# wsoc_nab_secure register map
Vendor: Texas Instruments
Peripheral module from a debugger description file (folder CC35X1E).
Registers are 32-bit, read-only, reset 0x0 unless marked. A register's access mark holds for its fields unless they carry their own. Offsets are as the file gives them; lines under a group give offsets from that group; [hi:lo] are bit positions; {n}, {i} and the like mark numbered series; 'fields as' and 'values as' point back to an identical list; <NAME> marks a mode.

## wsoc_nab_secure
0x00 nab_command_mailbox_address access per field
  [23:0] MEM_CMD_MBX_ADDR rw
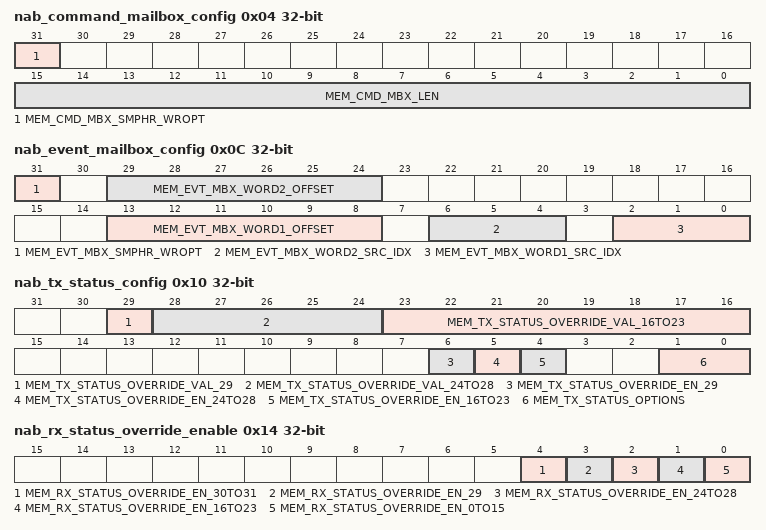
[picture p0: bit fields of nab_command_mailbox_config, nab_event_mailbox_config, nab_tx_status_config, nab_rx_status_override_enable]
0x04 nab_command_mailbox_config access per field
  [31] MEM_CMD_MBX_SMPHR_WROPT rw — Set to "1" by NAB H/W, when a new command arrives. Set to "0" by S/W (by actualy writing "1" to it, i.e. Write Clear) when the corresponding event has been submitted to NAB.
  [15:0] MEM_CMD_MBX_LEN rw — Command mailbox location. Once a command arrives, the fields from the opcode are dumped contiguously on this address. Aside from the opcode and length which are given in system endianness, the remainder of the command is in the endianness of the host.
0x08 nab_event_mailbox_address access per field
  [23:0] MEM_EVT_MBX_ADDR rw — Event mailbox location. S/W fills this block with data, including opcode and len fields, to be sent to the host in the appropriate cnys request. The len field must include the Rx status field, i.e., must be +4 then the remainder of the packet in the event mailbox.
0x0C nab_event_mailbox_config access per field
  [31] MEM_EVT_MBX_SMPHR_WROPT rw — Set to "1" by S/W, when the event address and length are filled up with a new event. Note that the NAB H/W then signals the host (IRQ line) when this is set, to ask the host to issue cnys request. Set to "0" by NAB, when the event has been fully consumed by the host.
  [29:24] MEM_EVT_MBX_WORD2_OFFSET rw — Indicates the added word nr.2 (if exists) offset location within the response sequence: "0" - N.A (this is OP-LEN field offset location) "1" - Place word nr.2 in word offset 1 (right after OP-LEN field) "2" - Place word nr.2 in word offset 2 "3" - Place word nr.2 in word offset 3 etc... NOTE: in WORD 2 exsits, WORD2_OFFSET > WORD1_OFFSET should be applied.
  [13:8] MEM_EVT_MBX_WORD1_OFFSET rw — Indicates the added word nr.1 (if exists) offset location within the response sequence: "0" - N.A (this is OP-LEN field offset location) "1" - Place word nr.1 in word offset 1 (right after OP-LEN field) "2" - Place word nr.1 in word offset 2 "3" - Place word nr.1 in word offset 3 etc...
  [6:4] MEM_EVT_MBX_WORD2_SRC_IDX rw — Nab supports adding info words toward host during event mailbox response. This field Indicates the source of word nr. 2: "0" - feature disabled (do not add any word). Nab transfers mailbox As-is. "1" - source is nab_srp_skt_not_empty_vec - the monitored-only Rx FIFO non-empty sockets (note that monitored sockets are configured in MEM_SRP_SKT_MONITORED_VEC) "2" - source is timer count. i.e. the always-on-domain counter is used. "3-6" - TBD "7" - source is an OCP mapped memory read (mostly for reading any register which is not mapped by index 1 to 6)
  [2:0] MEM_EVT_MBX_WORD1_SRC_IDX rw — Nab supports adding info words toward host during event mailbox response. This field Indicates the source of word nr. 1: "0" - feature disabled (do not add any word). Nab transfers mailbox As-is. "1" - source is nab_srp_skt_not_empty_vec - the monitored-only Rx FIFO non-empty sockets (note that monitored sockets are configured in MEM_SRP_SKT_MONITORED_VEC) "2" - source is timer count. i.e. the always-on-domain counter is used. "3-6" - TBD "7" - source is an OCP mapped memory read (mostly for reading any register which is not mapped by index 1 to 6)
0x10 nab_tx_status_config access per field
  [29] MEM_TX_STATUS_OVERRIDE_VAL_29 rw
  [28:24] MEM_TX_STATUS_OVERRIDE_VAL_24TO28 rw
  [23:16] MEM_TX_STATUS_OVERRIDE_VAL_16TO23 rw
  [6] MEM_TX_STATUS_OVERRIDE_EN_29 rw
  [5] MEM_TX_STATUS_OVERRIDE_EN_24TO28 rw
  [4] MEM_TX_STATUS_OVERRIDE_EN_16TO23 rw
  [1:0] MEM_TX_STATUS_OPTIONS rw — 00 - default: 1 word TX status 01 - Synced (wrapped): 3 words - Sync pattern,OP_LEN (LEN=4) and TX status. 11 - No status 10 - N.A In BSD_BYPASS=1 (Osprey) should be set to 11 - No Status
0x14 nab_rx_status_override_enable access per field
  [4] MEM_RX_STATUS_OVERRIDE_EN_30TO31 rw, [3] MEM_RX_STATUS_OVERRIDE_EN_29 rw, [2] MEM_RX_STATUS_OVERRIDE_EN_24TO28 rw, [1] MEM_RX_STATUS_OVERRIDE_EN_16TO23 rw, [0] MEM_RX_STATUS_OVERRIDE_EN_0TO15 rw
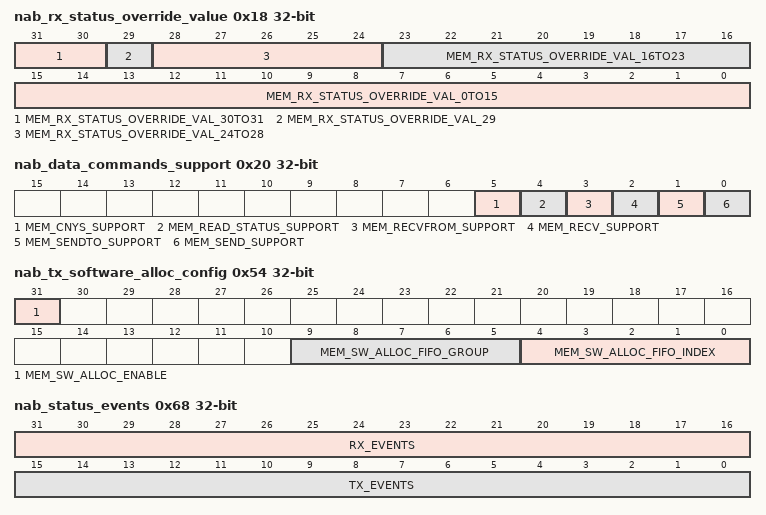
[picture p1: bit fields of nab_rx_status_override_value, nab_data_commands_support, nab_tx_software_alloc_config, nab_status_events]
0x18 nab_rx_status_override_value rw
  [31:30] MEM_RX_STATUS_OVERRIDE_VAL_30TO31, [29] MEM_RX_STATUS_OVERRIDE_VAL_29, [28:24] MEM_RX_STATUS_OVERRIDE_VAL_24TO28, [23:16] MEM_RX_STATUS_OVERRIDE_VAL_16TO23, [15:0] MEM_RX_STATUS_OVERRIDE_VAL_0TO15
0x1C nab_rx_pending_timeout_periord
  [31:0] Reserved — When timeout mechanism is supported in h/w (currently not), this register contains MEM_PENDING_TIMEOUT_PERIOD[29:0] that specify the time in AOD counter cycles between socket gets pending to socket expiry event (pending timeout duration).
0x20 nab_data_commands_support access per field reset not defined
  [5] MEM_CNYS_SUPPORT rw, [4] MEM_READ_STATUS_SUPPORT rw, [3] MEM_RECVFROM_SUPPORT rw, [2] MEM_RECV_SUPPORT rw, [1] MEM_SENDTO_SUPPORT rw, [0] MEM_SEND_SUPPORT rw
0x24 nab_d2h_sync_pattern rw
  [31:0] MEM_D2H_SYNC_PATTERN
0x28 nab_cnys_pattern rw reset not defined
  [31:0] MEM_CNYS_PATTERN
0x2C nab_sync_pattern rw reset not defined
  [31:0] MEM_SYNC_PATTERN
0x34 nab_tx_host_desc_config
  [31:0] TX_DESC_CONFIG
0x38 nab_tx_host_desc_port_padding
  [31:0] DESC_PORT_PADDING
{0x3C+4i} nab_tx_host_desc_peer_addr_w{i} (i=0..4)
  [31:0] DESC_PEER_ADDR_W{i}
0x50 nab_tx_host_tcw
0x54 nab_tx_software_alloc_config access per field reset not defined
  [31] MEM_SW_ALLOC_ENABLE rw — 1 - MMU Bypass mode: it is FW responsibility to allocate Pram for incoming TX Packet. 0 - Default mode: it is NAB responsibility to allocate Pram for incoming TX Packet.
  [9:5] MEM_SW_ALLOC_FIFO_GROUP rw — A User defined FIFO Group from which NAB obtains a descriptor index when SW_ALLOC_ENABLE=1. Otherwise, Nab obtains desc index from MMU.
  [4:0] MEM_SW_ALLOC_FIFO_INDEX rw — A User defined FIFO Index from which NAB obtains a descriptor index when SW_ALLOC_ENABLE=1. Otherwise, Nab obtains desc index from MMU. Elaboration: S/W Allocation is descriptor-index based. Each descriptor is mapped directly to a flat memory which contains a full sized packet (2KiB). This means that every packet consumes the same memory. A pool of free descriptors, and therefore, their associated memory packets are also available, is managed by a specially designated free descriptor index FIFO. Therefore, allocation is made by reading the FIFO and obtaining a real descriptor index (if the FIFO is empty, a null index is returned). Deallocation is done by writing to the FIFO a descriptor index to be freed.
0x58 nab_socket_max_index access per field reset not defined
  [4:0] MEM_SKT_MAX_IDX rw — indicated the maximun index of socket ID. implies on number of sockets (Nab POV) in the device. In case host request data comand (send(), recv() etc..) with socket ID bigger than this value, device responses w/ EBADF. Explicitly: 0 - socket 0 is can be issued by host 1 - sockets 0 and 1 can be issued by host 2 - sockets 0,1 and 2 can be issued by host 3 - sockets 0,1,2 and 3 can be issued by host .. .. .. 31 - sockets 0,1,2...,30,31 can be issued by host
0x5C nab_timeouted_socket_smphr rw
  [31:0] MEM_TIMEOUTED_SKT_SMPHR_WROPT — A bit per socket indicating this socket has been timeout. Set by H/W upon a PENDING socket reached it's timeout period. Reset by S/W upon data arrives to this socket or when it whishes to flush it. NOTE: when this bit set, H/W will keep socket in PENDING state even if it rx data FIFO is not empty.
0x60 nab_host_fifo_threshold access per field reset not defined
  [3:0] MEM_HOST_FIFO_TH rw — This number is the nab to host FIFO threshold. All reads issued to (by host) FIFO are stalled untill FIFO is filled above this threshold. Once the threshold reached FIFO is being read regardless of the threshold. Effective in RCV case only. The motivation is to avoid FIFO underflow. in Osprey (BSD_BYPASS = 1) this threshold is not applicable. The reason for that is that unlike SPI, in SDIO, we have back-pressure in the form of scmdaccept. The SDIO can store SDIO block and can bare the wait-states while waiting till Nab is ready to be read.
0x64 nab_cnys_select_config access per field
  [0] MEM_CNYS_SEL_ROUND_ROBIN rw — cyns response policy for active (cnysable) sockets: 0 - fix priority: selects socket with the lowest index. 1 - round robin priority: lowest index from last selected. Prevents socket starvation. default is fixed priority (0)
0x68 nab_status_events
  [31:16] RX_EVENTS, [15:0] TX_EVENTS
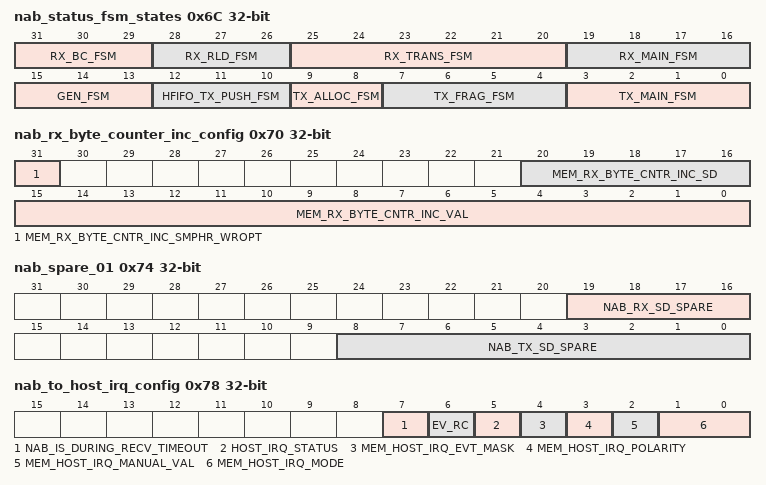
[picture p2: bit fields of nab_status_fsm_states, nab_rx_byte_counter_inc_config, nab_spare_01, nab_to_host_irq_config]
0x6C nab_status_fsm_states
  [31:29] RX_BC_FSM — ----- RX Byte Counter FSM ----------------------- BC_IDLE = 3'd0, GET_VAL = 3'd1, GET_SKT = 3'd2, V_S_CAP = 3'd3, BC_RD = 3'd4, BC_CAP = 3'd5, BC_WR = 3'd6; W_STATE = 3'd7;
  [28:26] RX_RLD_FSM — ----- RX RELOAD FSM ----------------------------- RLD_IDLE = 3'd0, RLD_GET_SKT = 3'd1, RLD_CAP_SKT = 3'd2, RLD_RD_TIMESTAMP = 3'd3, RLD_CAP_TIMESTAMP = 3'd4;
  [25:20] RX_TRANS_FSM — ----- RX TRANS FSM ------------------------------ TRANS_IDLE = 6'd0 , ------- collect ------- PEEK_VSUD = 6'd1 , CAP_VSUD = 6'd2 , COLLECT_SUD = 6'd3 , GET_NXT = 6'd4 , ACC_LEN = 6'd5 , ------- response ------- WAIT4_EMPTY = 6'd6 , SYNC = 6'd7 , OP_LEN = 6'd8 , RX_STATUS = 6'd9 , DESC_CFG = 6'd10, PORT_PAD = 6'd11, PEER_W0 = 6'd12, PEER_W1 = 6'd13, PEER_W2 = 6'd14, PEER_W3 = 6'd15, PEER_W4 = 6'd16, CAP_IP = 6'd17, SET_TCW = 6'd18, ------- payload ------- POP_VSUD = 6'd19, RD_SUD1 = 6'd20, RD_SUD2 = 6'd21, RD_PA = 6'd22, CAP_PA = 6'd23, RD_DATA = 6'd24, UPD_SUD1 = 6'd25, UPD_SUD2 = 6'd26, DEALLOC_SUD = 6'd27, DEALLOC_DESC = 6'd28, RCV_DONE = 6'd29, CHK_FIFO = 6'd30, BYTE_CNT_INC = 6'd31, BYTE_CNT_DEC = 6'd32, PUSH_HEAD = 6'd33; ADDR_CAP = 6'd34;
  [19:16] RX_MAIN_FSM — ----- RX MAIN FSM ------------------------------- IDLE = 4'd0, DESC = 4'd1, TCW = 4'd2, BUSY = 4'd3, HDR_DONE = 4'd4, SOCKET_RD = 4'd5, EVAL_REQ = 4'd6, RETAIN_SOCKET_STATE = 4'd7, COLLECT_LEN = 4'd8, RX_RESPONSE = 4'd9;
  [15:13] GEN_FSM — ----- GEN FSM ----------------------------------- IDLE = 4'd0 CAPTURE_OP_LEN = 4'd1 HANDLE_SND_REQ = 4'd2 HANDLE_RCV_REQ = 4'd3 CNYS_ON_RCV_BUSY = 4'd4 RCV_ON_RCV_BUSY = 4'd5 SND_ON_RCV_BUSY = 4'd6 CAPTURE_RX_DESC_CFG = 4'd7 CAPTURE_RX_TCW = 4'd8 (Apears as 0 as we occupied only 3 LSB's)
  [12:10] HFIFO_TX_PUSH_FSM — ----- Host FIFO TX PUSH FSM --------------------- TX_PUSH_IDLE = 3'd0, WAIT4_RCV_DONE = 3'd1, TX_PUSH_SYNC = 3'd2, TX_PUSH_OP_LEN = 3'd3, TX_PUSH_STATUS = 3'd4;
  [9:8] TX_ALLOC_FSM — ----- TX ALLOC FSM ------------------------------ GET_ALLOC_IDLE = 2'd0, GET_ALLOC_WR_REQ = 2'd1, GET_ALLOC_GET_IRQ = 2'd2, GET_ALLOC_RD_RSP = 2'd3;
  [7:4] TX_FRAG_FSM — ----- TX FRAGMENTATION FSM ---------------------- FRAG_IDLE = 4'b 0_0_0_0, // 0 FIRST_LAST = 4'b 0_1_1_1, // 7 FIRST_PRE_LAST = 4'b 0_1_0_1, // 5 FIRST = 4'b 1_1_0_1, // d MID = 4'b 0_1_0_0, // 4 PRE_LAST = 4'b 1_1_0_0, // c LAST = 4'b 0_1_1_0; // 6 bit[0]- first indication bit[1]- last indication bit[2]- tx desc write indication bit[3]- Unique bit
  [3:0] TX_MAIN_FSM — ----- TX MAIN FSM ------------------------------- IDLE = 4'd0, DESC = 4'd1, EVAL_REQ = 4'd2, DESC_SENDTO = 4'd3, TCW = 4'd4, SET_ALLOC = 4'd5, SET_DMA_TRANSFER = 4'd6, DMA_TRANSFER = 4'd7, SET_LAST_FRAG = 4'd8, PUSH = 4'd9, JOIN = 4'd10, DEALLOC = 4'd11, DROP_PACKET = 4'd12, ALLOC_FIRST = 4'd13, TX_STATUS = 4'd14;
0x70 nab_rx_byte_counter_inc_config access per field
  [31] MEM_RX_BYTE_CNTR_INC_SMPHR_WROPT rw — Set to "1" by S/W once an rx packet arrives to rx pipeline. Set to "0" by H/W once the NAB acknowledges the S/W request to increment (in a signed way) the byte counter
  [20:16] MEM_RX_BYTE_CNTR_INC_SD rw — Identifies the socket ID (socket database's entry) for which Rx byte count is to be updated.
  [15:0] MEM_RX_BYTE_CNTR_INC_VAL rw — The value designates a signed 16 bit value to be added (or decremented if negative) to a given socket's Rx byte count. The NAB would update the relevant Rx byte count safely using MEM_RX_BYTE_COUNTER_SMPHR. Protocol: 1. The S/W determines the size to be added to the Rx byte count, once a new packet arrives to the pipe. 2. The S/W then writes to this register the value comprising both the socket (MEM_RX_BYTE_CNTR_INC_SD) and number to add (MEM_RX_BYTE_CNTR_INC_VAL). 3. NAB H/W safely updates the socket entry.
0x74 nab_spare_01
  [19:16] NAB_RX_SD_SPARE — For future ECO usage. H/W gets socket database info per socket
  [8:0] NAB_TX_SD_SPARE — For future ECO usage. H/W gets socket database info per socket
0x78 nab_to_host_irq_config access per field
  [7] NAB_IS_DURING_RECV_TIMEOUT ro — Indication that Nab got recv request to socket with no data (empty fifo) and recv tiomeout indication at this socket is set. Nab sets this socket to PENDING state, reads current timest + timeout period and waits for either data arrival to this socket fifo or to timeout expiry event.
  [6] EV_RC ro — Event-Receive Bit: 1 - at least one of 32 sockets is in Active state (a pending socket that is now ready to be issued) OR S/W set Event MBX semaphore and CNYS is yet to arrive (EVT-MBX contains unissued event) 0 - No Active socket and Event Mailbox is empty. Note: 1. ev_rc bit is the Host IRQ initiator. In "Level mode" IRQ: ec_rc == HOST_IRQ_STATUS. In other modes - this bit is manipulated in order to create proper IRQ line toward the host. 2. A mask bit per socket, mem_host_irq_rcv_mask[31:0], can be set in order to prevent ev_rc 3. A mask bit, mem_host_irq_evt_mask, can be set in order to prevent ev_rc
  [5] HOST_IRQ_STATUS ro — Presents status of IRQ line using positive polarity.
  [4] MEM_HOST_IRQ_EVT_MASK rw — "1" Disable the event mailbox as a host IRQ trigger "0" Enable the event mailbox as a host IRQ trigger
  [3] MEM_HOST_IRQ_POLARITY rw — "1" for negative polarity "0" for positive polarity (GuyS: in order to preserve this at sleep (retention) - ISO latch needs to be implementd. Alternatively, move this polarity cfg bit to upper H/W layer above Nab)
  [2] MEM_HOST_IRQ_MANUAL_VAL rw — Defines the value of the host IRQ line in manual mode operation
  [1:0] MEM_HOST_IRQ_MODE rw — Defines the method of operation of the host IRQ line: "00" Manual "01" CC31xx level mode of operation "10" Level mode of operation "11" Edge mode of operation
0x7C nab_to_host_irq_rcv_mask rw
  [31:0] MEM_HOST_IRQ_RCV_MASK — Bit per socket filed. bit x = "1": Disable the Active Rx socket nr. x as a host IRQ trigger bit x = "0": Enable the Active Rx socket nr. x as a host IRQ trigger
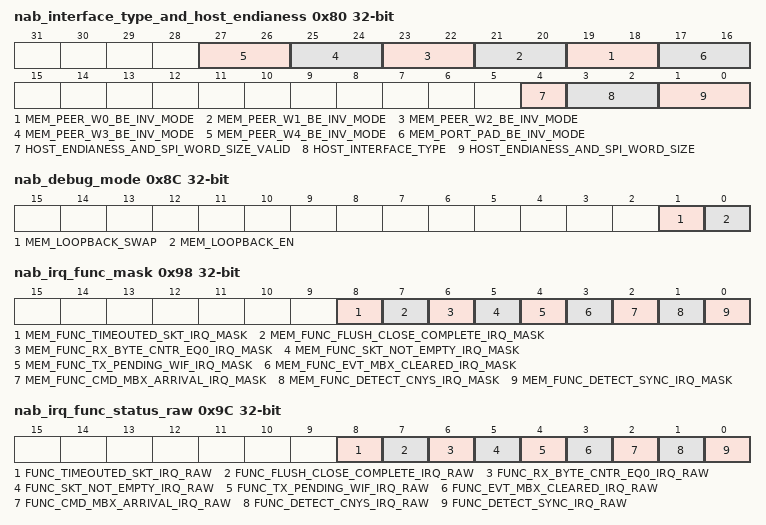
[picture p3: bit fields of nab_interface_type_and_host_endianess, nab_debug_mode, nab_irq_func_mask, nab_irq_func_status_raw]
0x80 nab_interface_type_and_host_endianess access per field
  [2n+19:2n+18] MEM_PEER_W{n}_BE_INV_MODE rw (n=0..4) — Multi byte field inversion of peer parameters for Big Endianess host: 0 - no inversion (in case word structure is four 8-bit integers). 1 - word 2B/2B byte inversion (in case word structure is 2 shorts). 2 - full 4B inversion (in case word structure 32-bit integer). 3 - N.A
  [17:16] MEM_PORT_PAD_BE_INV_MODE rw — Multi byte field inversion of peer parameters for Big Endianess host: 0 - no inversion (in case word structure is four 8-bit integers). 1 - word 2B/2B byte inversion (in case word structure is 2 shorts). 2 - full 4B inversion (in case word structure 32-bit integer). 3 - N.A
  [4] HOST_ENDIANESS_AND_SPI_WORD_SIZE_VALID ro — Indicates host's endianess and SPI word size. 0 - LE-32, 1 - LE-16, 2 - LE-8, 3 - BE, Note: assumption is that SPI interfaces works MSB first.
  [3:2] HOST_INTERFACE_TYPE ro — Indicates Interface Type according to input ports (from Nab interface adaptor). 0 - AHB 1 - SPI 2 - UART 3 - Undetected_yet. No cnys/sync detection occurred. NOTE: HOST_INTEWRFACE TYPE = 3 means that no SYNC/CNYS detection occurred. therfore, the content of HOST_ENDIANESS_AND_SPI_WORD_SIZE is not valid as well. SW should read these fielsd only after SYNC/CNYS detect interrupt are set. IMPORTANT: Currrently it is hard coded, tied in h/w value: in BSD_BYPASS=1 (Osprey) tied to 3. in BSD_BYPASS=0 (Not Osprey) tied to 1.
  [1:0] HOST_ENDIANESS_AND_SPI_WORD_SIZE ro — Indicates host's endianess and SPI word size. 0 - LE-32, 1 - LE-16, 2 - LE-8, 3 - BE, Note: assumption is that SPI interfaces works MSB first.
0x84 nab_socket_state_00_to_15 rw
  [31:0] MEM_SOCKET_STATE_00_TO_15_WROPT — Socket 0 to 15 state register: bit [2x+1:2x] = "00" - Socket x is IDLE "01" - Socket x is Pending "10" - Socket x is Active "11" - N.A Pending state occurs when blocking socket recives host request and related Rx FIFO is empty. Active state occurs when pending socket recives data or pending-timeout occurs. Active means that the socket is applicable for CNYS. NOTE: 1. Socket that is not pending and not active is considered to be IDLE, i.e. ready to receive host request. 2. S/W can write this reg. This enable restoring socket state after ELP. writing less than a byte is not allowed. 3. If socket is written by S/W as PENDING it will be considered as if no timeout was enabled (we cannot restore a socket to PENDING with timeout period on).
0x88 nab_socket_state_16_to_31 rw
  [31:0] MEM_SOCKET_STATE_16_TO_31_WROPT — Socket 16 to 31state register: bit [2x+1:2x] = "00" - Socket 16+x is IDLE "01" - Socket 16+x is Pending "10" - Socket 16+x is Active "11" - N.A Pending state occurs when blocking socket recives host request and related Rx FIFO is empty. Active state occurs when pending socket recives data or pending-timeout occurs. Active means that the socket is applicable for CNYS. NOTE: 1. Socket that is not pending and not active is considered to be IDLE, i.e. ready to receive host request. 2. S/W can write this reg. This enable restoring socket state after ELP. writing less than a byte is not allowed. 3. If socket is written by S/W as PENDING it will be considered as if no timeout was enabled (we cannot restore a socket to PENDING with timeout period on).
0x8C nab_debug_mode access per field
  [1] MEM_LOOPBACK_SWAP rw — 0 - loopback word swap is disabled 1 - loopback word swap is enabled when loopback mode is enabled, nab examines the host incoming words and search for a pre defined pattern. Once this pattern is detected, it is swapped (16 LSB and 16 MSB are swiched) before pushing it back to host like any other word. The pre define pattern, `LOOPBACK_WORD, can be found in wsoc_nab_defines.v e.g. word pattern: 0x76543210 host stream to nab: ...,0x49a9, 0x5, 0x8675d, 0x7653b, 0x76543210, 0x6745b3c, 0x65d,... nab stream back to host: ...,0x49a9, 0x5, 0x8675d, 0x7653b, 0x32107654, 0x6745b3c, 0x65d,...
  [0] MEM_LOOPBACK_EN rw — 0 - loopback mode is disabled 1 - loopback mode is enabled In Loopback mode any word written by host to nab via data ocp slave port is returned back to host. Nab pushes the incoming word straight to FIFO toward host.
0x90 nab_flush_close_command_sel access per field
  [0] MEM_FLUSH_CLOSE_SEL rw — 1 - FLUSH command 0 - CLOSE command
0x94 nab_flush_close_command_smphr rw
  [31:0] MEM_FLUSH_CLOSE_SMPHR_WROPT — Bit per socket that supports Both FLUSH and CLOSE commands request (according to MEM_FLUSH_CLOSE_SEL) settings at the time of the request: Set to "1" by SW as request to flush or close request (one at a time), possibly to more than one socket. Set to "0" by H/W once command is completed FLUSH: Once set by S/W Nab looks for the nearest opportunity to clear it, indicating that the socket is flushed. The nearest opportunity is as follow: in case socket is occupied - wait till it clears. In case socket is not occupied and not pending - the socket can be "Flushed" immediately. Nab Clears the semaphore and triggers S/W with flush_close IRQ. In case socket is not occupied but is pending - the socket cannot be "Flushed" immediately. Nab moves the socket to active and waits for host CNYS. Once arrived, answer the CNYS with Disallowed (and not ENODATAC), clears the semaphore and triggers S/W with flush_close IRQ. NOTE: it is NWP S/W responsibility to disallowed the socket before flushing it. CLOSE: Once set by S/W Nab looks for the nearest opportunity to clear it, indicating that the socket is closed. The nearest opportunity is as follow: in case socket is occupied - wait till it clears. In case socket is not occupied - the socket can be "Closed" immediately. Nab Clears the semaphore and triggers S/W with flush_close IRQ. NOTE: it is NWP S/W responsibility to close socket only if it is in IDLE state (and after closing the socket, i.e. setting "111...", in socket jump table).
0x98 nab_irq_func_mask access per field — Mask interrupt bits: when set to "1", the interrupt is masked, and NOT be reflected to user.
  [8] MEM_FUNC_TIMEOUTED_SKT_IRQ_MASK rw, [7] MEM_FUNC_FLUSH_CLOSE_COMPLETE_IRQ_MASK rw, [6] MEM_FUNC_RX_BYTE_CNTR_EQ0_IRQ_MASK rw, [5] MEM_FUNC_SKT_NOT_EMPTY_IRQ_MASK rw, [4] MEM_FUNC_TX_PENDING_WIF_IRQ_MASK rw, [3] MEM_FUNC_EVT_MBX_CLEARED_IRQ_MASK rw, [2] MEM_FUNC_CMD_MBX_ARRIVAL_IRQ_MASK rw, [1] MEM_FUNC_DETECT_CNYS_IRQ_MASK rw, [0] MEM_FUNC_DETECT_SYNC_IRQ_MASK rw
0x9C nab_irq_func_status_raw — Unmasked Interrupt status bits.
  [8] FUNC_TIMEOUTED_SKT_IRQ_RAW, [7] FUNC_FLUSH_CLOSE_COMPLETE_IRQ_RAW, [6] FUNC_RX_BYTE_CNTR_EQ0_IRQ_RAW, [5] FUNC_SKT_NOT_EMPTY_IRQ_RAW, [4] FUNC_TX_PENDING_WIF_IRQ_RAW, [3] FUNC_EVT_MBX_CLEARED_IRQ_RAW, [2] FUNC_CMD_MBX_ARRIVAL_IRQ_RAW, [1] FUNC_DETECT_CNYS_IRQ_RAW, [0] FUNC_DETECT_SYNC_IRQ_RAW
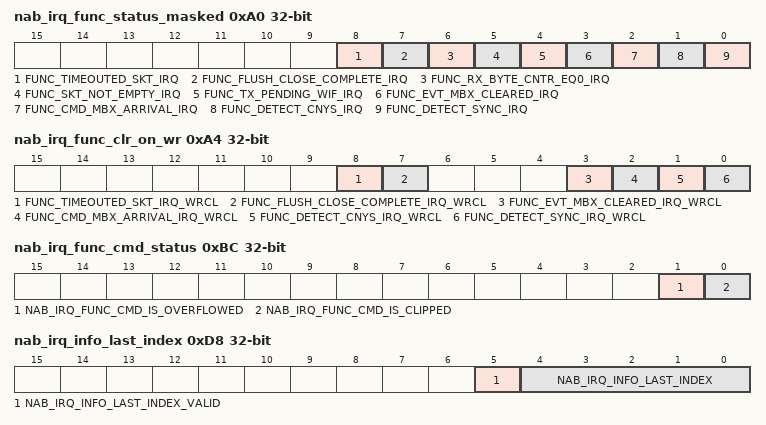
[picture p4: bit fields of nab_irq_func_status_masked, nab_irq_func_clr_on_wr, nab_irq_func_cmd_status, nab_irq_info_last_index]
0xA0 nab_irq_func_status_masked — Interrupt status bits - Masked according to NAB_IRQ_FUNC_MASK.
  [8] FUNC_TIMEOUTED_SKT_IRQ — Set by H/W upon socket's PENDING period timeout has reached. Clear by S/W using FUNC_TIMEOUTED_SKT_IRQ_WRCL.
  [7] FUNC_FLUSH_CLOSE_COMPLETE_IRQ — Set by H/W upon completion of S/W "Flush" or "Close" request (one socket or more). Clear by S/W using FUNC_FLUSH_CLOSE_COMPLETE_IRQ_WRCL. NOTE: the IRQ is set at even if there are othere sockets with ongoing Flush/Close requests.
  [6] FUNC_RX_BYTE_CNTR_EQ0_IRQ — Set by H/W when at least one bit of NAB_IRQ_FUNC_RX_BC0_SKT_IDX is set to "1". Clear by H/W when All bits of NAB_IRQ_FUNC_RX_BC0_SKT_IDX are equal to "0".
  [5] FUNC_SKT_NOT_EMPTY_IRQ — Set by H/W when at least one bit of NAB_SRP_SKT_NOT_EMPTY_VEC is set to "1". Clear by H/W when All bits of NAB_SRP_SKT_NOT_EMPTY_VEC are equal to "0".
  [4] FUNC_TX_PENDING_WIF_IRQ — Set by H/W when at least one bit of NAB_IRQ_FUNC_TX_WIF_SKT_IDX is set to "1". Clear by H/W when All bits of NAB_IRQ_FUNC_TX_WIF_SKT_IDX are equal to "0".
  [3] FUNC_EVT_MBX_CLEARED_IRQ — Set by H/W upon reading ALL data from event mailbox. Clear by S/W using FUNC_EVT_MBX_ARRIVAL_IRQ_WRCL.
  [2] FUNC_CMD_MBX_ARRIVAL_IRQ — Set by H/W upon generic Command detection from host. Clear by S/W using FUNC_CMD_MBX_ARRIVAL_IRQ_WRCL.
  [1] FUNC_DETECT_CNYS_IRQ — Set by H/W upon CNYS word detection from host. Clear by S/W using FUNC_DETECT_CNYS_IRQ_WRCL.
  [0] FUNC_DETECT_SYNC_IRQ — Set by H/W upon SYNC word detection from host. Clear by S/W using FUNC_DETECT_SYNC_IRQ_WRCL.
0xA4 nab_irq_func_clr_on_wr access per field — Interrupt status clear bits. (clear on WR "1")
  [8] FUNC_TIMEOUTED_SKT_IRQ_WRCL wo, [7] FUNC_FLUSH_CLOSE_COMPLETE_IRQ_WRCL wo, [3] FUNC_EVT_MBX_CLEARED_IRQ_WRCL wo, [2] FUNC_CMD_MBX_ARRIVAL_IRQ_WRCL wo, [1] FUNC_DETECT_CNYS_IRQ_WRCL wo, [0] FUNC_DETECT_SYNC_IRQ_WRCL wo
0xA8 nab_irq_func_tx_wif_skt_idx — Information saved for the interrupt func_tx_pending_wif_irq: bits[31:0] - bit per socket. 1 - This socket has failed to serve a blocking send/sendto operation due to insufficient mem/blk 0 - This socket has NOT failed to serve a blocking send/sendto operation.
0xAC nab_irq_func_tx_wif_skt_idx_clr_on_wr wo — Clear Information saved for the interrupt func_tx_wif_irq: bits[31:0] - bit per socket. 1 - Clear the related socket information bit 0 - Socket's information bit is unchanged
  [31:0] MEM_NAB_IRQ_FUNC_TX_WIF_WRCL
0xB0 nab_irq_func_rx_bc0_skt_idx_en rw — Information configured for the interrupt func_rx_byte_cntr_bc0_irq: bits[31:0] - bit per socket. 1 - Enable "byte counter equal to zero" interrupt for this socket. 0 - Do not set "byte counter equal to zero" interrupt for this socket.
  [31:0] MEM_BYTE_CNTR_EQ_0_INT_EN
0xB4 nab_irq_func_rx_bc0_skt_idx — Information saved for the interrupt func_rx_byte_cntr_bc0_irq: bits[31:0] - bit per socket. 1 - This socket byte counter has just been updated to zero by h/w due to RX descriptor deallocation process. 0 - This socket byte counter has NOT been updated to zero.
0xB8 nab_irq_func_rx_bc0_skt_idx_clr_on_wr wo — Clear Information saved for the interrupt func_rx_byte_cntr_bc0_irq: bits[31:0] - bit per socket. 1 - Clear the related socket information bit 0 - Socket's information bit is unchanged
  [31:0] MEM_NAB_IRQ_FUNC_RX_BC0_WRCL
0xBC nab_irq_func_cmd_status
  [1] NAB_IRQ_FUNC_CMD_IS_OVERFLOWED — SEVERE generic CMD failure: Tx detect overflow during host generic CMD handling (copy data to Mailbox)
  [0] NAB_IRQ_FUNC_CMD_IS_CLIPPED — SEVERE generic CMD failure: t.len < CMD Mailbox size defined by MEM_CMD_MBX_LEN
0xC0 nab_ready access per field
  [0] MEM_NAB_READY rw — 1 - Nab is ready and will monitor host bus for sync/cnys patterns 0 - Nab is not ready and will not monitor host bus for sync/cnys patterns Default is 0
0xC4 nab_irq_info_mask rw — Mask interrupt bits. when set, bit x masks interrupt nr. x. refer to NAB_IRQ_INFO_STATUS_MASKED register for info inrerrupts list
  [31:0] MEM_NAB_IRQ_INFO_MASK
0xC8 nab_irq_info_status_raw — Unmasked Interrupt status bits. bit x states interrupt nr. x refer to NAB_IRQ_INFO_STATUS_MASKED register for info inrerrupts list
0xCC nab_irq_info_status_masked — Interrupt status bits - Masked according to NAB_IRQ_INFO_MASK. INFO Interrupt list: 0 - detect_rcv_cnys ; Operation started - rcv_cnys 1 - detect_evt_cnys ; Operation started - evt_cnys 2 - detect_rds_cnys ; Operation started - rds_cnys 3 - detect_send ; Operation started - send() 4 - detect_sendto ; Operation started - sendto() 5 - detect_recv ; Operation started - recv() 6 - detect_recvfrom ; Operation started - recvfrom() 7 - detect_read_status ; Operation started - read_status() 8 - detect_cmd ; Operation started - generic cmd 9 - rcv_header_done ; Operation ended (Rx header recived at nab) - recv()/recvfrom() 10 - snd_done ; Response (Operation) ended - send()/sendto() (bits 23:22 in info word, desc-cfg, use for opcode decode) 11 - rds_done ; Response (Operation) ended - rd_status() is done 12 - rcv_done ; Response ended - recv()/recvFrom() (bits 23:22 in info word, desc-cfg, use for opcode decode) 13 - cmd_done ; Response ended - generic cmd is fully copied to cmd mbx 14 - evt_done ; Response ended - event from s/w to host is fully sent toward host 15 - err_ebadf ; tx request failure: socket ID > mem_num_of_sockets or socket is not open 16 - err_disallowed ; tx request failure: detect send/sentTo request but send/sentTo is dissallowed 17 - err_eafnosupport ; tx request failure: address family is not allowed - sendTo only 18 - err_emsgsize ; tx request failure: user payload len exceeded socket's max_payload_size 19 - f_alloc_failure ; tx mem resource failure: first fragment MMU request alloc failure 20 - m_alloc_failure ; tx mem resource failure: middle fragment, RIGID socket, MMU request alloc failure - command aborted 21 - m_alloc_partial_len ; tx mem resource missing: middle fragment, Non-RIGID socket, MMU request alloc failure - command success for partial length 22 - err_ewouldblocks ; tx packet_failure_non_blk: mem resource failure (either one of f_alloc_failure, m_alloc_failure or sw_alloc_failure) on a Non-blocking socket 23 - err_enomem ; tx packet_failure_blk : mem resource failure (either one of f_alloc_failure, m_alloc_failure or sw_alloc_failure) on a Blocking socket 24 - err_ebadf ; rx request failure: socket ID > mem_num_of_sockets or socket is not open 25 - err_disallowed ; rx request failure: detect recv/recvFrom request but recv/recvFrom is dissallowed 26 - err_einexe ; rx request failure: detect recv/recvFrom request for PENDING/ACTIVE socket and multiple_recv option is off. 27 - err_einexeselet ; rx request failure: request for socket that is marked for select response monitoring. 28 - err_ewouldblockr ; rx no data failure: detect recv/recvFrom request for non-blocking socket with no data 29 - err_enodatap ; rx no data failure: detect recv/recvFrom request for blocking "IDLE" socket with no data (set socket to "PENDING") 30 - err_enodatac ; rx no data failure: detect CNYS request for blocking "PENDING"/"ACTIVE" socket with no data (which implies that socket got into "ACTIVE" due to timeout) 31 - err_enodatar ; rx no bound failure: detect request over strict socket but no packet boundary is found in sub-desc collection process
0xD0 nab_irq_info_clr_on_wr wo — Interrupt status clear bits. (clear on WR "1") bit x clears interrupt nr. x. refer to NAB_IRQ_INFO_STATUS_MASKED register for info inrerrupts list
  [31:0] MEM_NAB_IRQ_INFO_CLR_WRCL
0xD4 nab_irq_info_word — Information saved for the INFO interrupt: (0 - detect_rcv_cnys ; No info is saved. No info word latching occurs.) (1 - detect_evt_cnys ; No info is saved. No info word latching occurs.) (2 - detect_rds_cnys ; No info is saved. No info word latching occurs.) 3 - detect_send ; transport_op_len 4 - detect_sendto ; transport_op_len 5 - detect_recv ; transport_op_len 6 - detect_recvfrom ; transport_op_len 7 - detect_read_status ; transport_op_len 8 - detect_cmd ; transport_op_len 9 - rcv_header_done ; rx_desc_config_word (bits 23:22 are taken for opcode decode)* 10 - snd_done ; tx_desc_config_word (bits 23:22 are taken for opcode decode)* (11 - rds_done ; No info is saved. No info word latching occurs.) 12 - rcv_done ; rx_desc_config_word (bits 23:22 are taken for opcode decode)* 13 - cmd_done ; transport_op_len 14 - evt_done ; transport_op_len (as read from EVT mailbox) 15 - err_ebadf ; tx_desc_config_word (bits 23:22 are taken for opcode decode)* 16 - err_disallowed ; tx_desc_config_word (bits 23:22 are taken for opcode decode)* 17 - err_eafnosupport ; tx_desc_config_word (bits 23:22 are taken for opcode decode)* 18 - err_emsgsize ; tx_desc_config_word (bits 23:22 are taken for opcode decode)* 19 - f_alloc_failure ; tx_desc_config_word (bits 23:22 are taken for opcode decode)* 20 - m_alloc_failure ; tx_desc_config_word (bits 23:22 are taken for opcode decode)* 21 - m_alloc_partial_len; tx_desc_config_word (bits 23:22 are taken for opcode decode)* 22 - err_ewouldblocks ; tx_desc_config_word (bits 23:22 are taken for opcode decode)* 23 - err_enomem ; tx_desc_config_word (bits 23:22 are taken for opcode decode)* 24 - err_ebadf ; rx_desc_config_word (bits 23:22 are taken for opcode decode)* 25 - err_disallowed ; rx_desc_config_word (bits 23:22 are taken for opcode decode)* 26 - err_einexe ; rx_desc_config_word (bits 23:22 are taken for opcode decode)* 27 - err_einexeselect ; rx_desc_config_word (bits 23:22 are taken for opcode decode)* 28 - err_ewouldblockr ; rx_desc_config_word (bits 23:22 are taken for opcode decode)* 29 - err_enodatap ; rx_desc_config_word (bits 23:22 are taken for opcode decode)* 30 - err_enodatac ; rx_desc_config_word (bits 23:22 are taken for opcode decode)* 31 - err_enodatar ; rx_desc_config_word (bits 23:22 are taken for opcode decode)* where, transport_op_len[15:0] - Host opcode transport_op_len[31:16] - Host length desc_config_word[15:0] - User Length desc_config_word[20:16] - Socket ID desc_config_word[31:24] - Flags * rx_desc_config_word[23:22] opcode decode: 0 - cnys, 1 - recvfrom(), 2 - recv() * tx_desc_config_word[23:22] opcode decode: 1 - sendto() , 2 - send()
0xD8 nab_irq_info_last_index — Indicated Last Unmasked Interrupt index. index x states interrupt nr. x refer to NAB_IRQ_INFO_STATUS_MASKED register for info inrerrupts list
  [5] NAB_IRQ_INFO_LAST_INDEX_VALID, [4:0] NAB_IRQ_INFO_LAST_INDEX
0xDC nab_irq_err_mask access per field — Mask interrupt bits. when set, bit x masks interrupt nr. x. refer to NAB_IRQ_ERR_STATUS_MASKED register for err inrerrupts list
  [8:0] MEM_NAB_IRQ_ERR_MASK rw
0xE0 nab_irq_err_status_raw — Unmasked Interrupt status bits. bit x states interrupt nr. x refer to NAB_IRQ_ERR_STATUS_MASKED register for err inrerrupts list
  [8:0] NAB_IRQ_ERR_STATUS_RAW
0xE4 nab_irq_err_status_masked — Interrupt status bits - Masked according to NAB_IRQ_ERR_MASK. ERR Interrupt list: 0 - Tx detect_overflow (snd_abort) ; SEVERE transport error. Overflow at Host Tx bus (host to Device transport). Indication from uper layer outside Nab 1 - Rx detect_underflow ; SEVERE transport error. Underflow at Host Rx bus (Device to host transport). gost FIFO is empty recv transport. 2 - Tx common_err_einval ; SEVERE request failure: Tx Invalid Len, t.len < 4 or t.len < 8 when tcw is present 3 - Tx common_err_ebadlen ; SEVERE request failure: Tx Incompatible Len, desc_len != user payload len (calculated from t.len) or user payload len == 0 4 - Tx common_err_ebaduserlens ; SEVERE request failure: Tx Bad User Len, desc_len >= 32K or equal to 0 5 - Tx sw_alloc_failure ; SEVERE mem resource failure: SW address is not free - semaphore violation 6 - Rx common_err_einval ; SEVERE request failure: Rx Invalid Len, t.len != 4 or t.len != 8 when tcw is present 7 - Rx common_err_ebaduserlenr ; SEVERE request failure: Rx Bad User Len, desc_len >= 32K or equal to 0 8 - Rx detect_cmd_violation ; SEVERE generic CMD failure: commands arrives while mailbox is occupied with previous command and not yet cleared by S/W
  [8:0] NAB_IRQ_ERR_STATUS_MASKED
0xE8 nab_irq_err_clr_on_wr access per field — Interrupt status clear bits. (clear on WR "1") bit x clears interrupt nr. x. refer to NAB_IRQ_ERR_STATUS_MASKED register for err inrerrupts list
  [8:0] MEM_NAB_IRQ_ERR_CLR_WRCL wo
0xEC nab_irq_err_word — Information saved for the ERR interrupt: 0 - snd_abort ; transfer_op_len 1 - Rx detect_underflow ; {30'b0,recv,recvfrom} (bits 1:0 are used for opcode decode)* 2 - Tx common_err_einval ; tx_desc_config (bits 23:22 are taken for opcode decode)* 3 - Tx common_err_ebadlen ; tx_desc_config (bits 23:22 are taken for opcode decode)* 4 - Tx common_err_ebaduserlens ; tx_desc_config (bits 23:22 are taken for opcode decode)* 5 - Tx sw_alloc_failure ; tx_desc_config (bits 23:22 are taken for opcode decode)* 6 - Rx common_err_einval ; rx_desc_config (bits 23:22 are taken for opcode decode)* 7 - Rx common_err_ebaduserlenr ; rx_desc_config (bits 23:22 are taken for opcode decode)* 8 - Rx detect_cmd_violation ; transfer_op_len where, transport_op_len[15:0] - Host opcode transport_op_len[31:16] - Host length desc_config_word[15:0] - User Length desc_config_word[20:16] - Socket ID desc_config_word[31:24] - Flags * rx_desc_config_word[23:22] opcode decode: 0 - cnys, 1 - recvfrom(), 2 - recv() * tx_desc_config_word[23:22] opcode decode: 1 - sendto() , 2 - send() NOTE: snd_abort is relevant only if snd aborts during snd
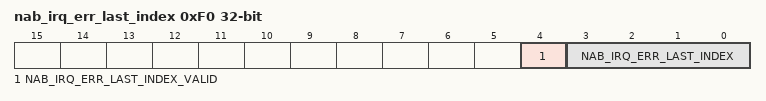
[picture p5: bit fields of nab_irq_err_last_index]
0xF0 nab_irq_err_last_index — Indicated Last Unmasked Interrupt index. index x states interrupt nr. x refer to NAB_IRQ_ERR_STATUS_MASKED register for err inrerrupts list
  [4] NAB_IRQ_ERR_LAST_INDEX_VALID, [3:0] NAB_IRQ_ERR_LAST_INDEX
0xF4 nab_srp_skt_monitored rw
  [31:0] MEM_SRP_SKT_MONITORED_VEC — Bit per socket. Indicates for which sockets, the NAB shall monitor their Rx FIFO, and when they become non-empty, shall trigger the select-response monitor IRQ
0xF8 nab_srp_skt_prevented rw
  [31:0] MEM_SRP_SKT_PREVENTED_VEC — Bit per soket. Indicates which sockets shall be denied recv/recvfrom requests with EINEXESELECT error.
0xFC nab_srp_skt_not_empty
  [31:0] NAB_SRP_SKT_NOT_EMPTY_VEC — Bit per Socket. Indicate which monitored(!) sockets have non-zero Rx FIFO. (note that monitored sockets are configured in MEM_SRP_SKT_MONITORED_VEC)
0x100 nab_statistics_count_0
  [31:0] COUNT_INFO_CNYS_RCV
0x104 nab_statistics_count_1
  [31:0] COUNT_INFO_CNYS_EVT
0x108 nab_statistics_count_2
  [31:0] COUNT_INFO_CNYS_RD_STATUS
0x10C nab_statistics_count_3
  [31:0] COUNT_INFO_SEND
0x114 nab_statistics_count_4
  [31:0] COUNT_INFO_SENDTO
0x118 nab_statistics_count_5
  [31:0] COUNT_INFO_RECV
0x11C nab_statistics_count_6
  [31:0] COUNT_INFO_RECVFROM
0x120 nab_statistics_count_7
  [31:0] COUNT_INFO_READ_STATUS
0x124 nab_statistics_count_8
  [31:0] COUNT_INFO_CMD
0x128 nab_rx_status_read
  [31:0] RX_STATUS — Reflects the Rx status word current value (dynamic Read). Nothing automatic occurs upon this read. This RX status word is similiar to the one that exist in the Nab response header (that is used in BSD_BYPASS=0 bt the host driver) with the following exceptions: 0to15 - rx byte counter[15:0] - In OSPREY (parameter BSD_BYPASS is equal to 1 by design) - The number of byte counter in socket. Managed by Nab H/W. Not in Osprey (parameter BSD_BYPASS is equal to 0 by design) - Unused. equal to 0. 16to23 - num_of_tx_blk[7:0] - In OSPREY (parameter BSD_BYPASS is equal to 1 by design) - The RX_STATUS_OVERRIDE_ENABLE will be set and S/W will place here the "Tx result Table index". Not in Osprey (parameter BSD_BYPASS is equal to 0 by design) - Remaining Tx Blocks in the Tx chain (in PRAM). Based on MMU H/W indications. 24to28 - num_of_tx_desc[4:0] - In OSPREY (parameter BSD_BYPASS is equal to 1 by design) - The RX_STATUS_OVERRIDE_ENABLE will be set and S/W will place here the "Event size" (payload+ status). Not in Osprey (parameter BSD_BYPASS is equal to 0 by design) - Remaining of Virtual Descriptors in the Tx chain (in PRAM). Based on MMU H/W indications. 29 - ev_rc - In OSPREY (parameter BSD_BYPASS is equal to 1 by design) - Unused. equal to 0. ( No "event receive" indication. The HINT register will be used for signaling to the host). Not in Osprey (parameter BSD_BYPASS is equal to 0 by design) - event receive indication. Signaling the host for pending Event or pending receive socket. 30to31 - event_id[1:0] - In OSPREY (parameter BSD_BYPASS is equal to 1 by design) - The RX_STATUS_OVERRIDE_ENABLE will be set and S/W will place here the "Event ID" (Event Counter modulo 4). Not in Osprey (parameter BSD_BYPASS is equal to 0 by design) - Unused. equal to 0.
0x12C nab_rx_status_read_and_latch
  [31:0] RX_STATUS_RDCL — Reflects the Rx status word current value (dynamic Read). and automatically latch the value in RX_STATUS_LATCHED. Usage: SDIO Wrapper reads this location and send the read value toward the host. For bit field description refer to RX_STATUS. This register is valid only in BSD_BYPASS=1 (Osprey).
0x130 nab_rx_status_read_latched_val
  [31:0] RX_STATUS_LATCHED — Reflects the Rx status word latched value (static Read). Nothing automatically occurs upon this read. Usage: S/W reads this location in order to know what value has been delivered to Host by SDIO Wrapper. For bit field description refer to RX_STATUS. This register is valid only in BSD_BYPASS=1 (Osprey).
0x134 nab_hint_status_clr_on_rd
  [31:0] HINT_STATUS_RDCL — Host interrupt status clear-on-read register Clears all bits of upon read. Usage: host reads the IRQ register which is automatically getting cleared by H/W Osprey Note: The endianness correction and word-size correction are done in SDIO(WSPI) H/W.
0x138 nab_hint_set wo
  [31:0] HINT_SET_WRCL — Host interrupt set register
0x13C nab_hint_clr wo
  [31:0] HINT_CLR_WRCL — Host interrupt clear register
0x140 nab_hint_status_raw
  [31:0] HINT_STATUS_RAW — Host interrupt status read register. non-intrusive read. Pre mask (raw).
0x144 nab_hint_status_masked
  [31:0] HINT_STATUS_MASKED — Host interrupt status read register. non-intrusive read. Post mask (masked).
0x148 nab_hint_mask_set wo
  [31:0] HINT_MASK_SET_WRCL — Host interrupt mask register set Writing to this regidster will set to '1' the related interrupt mask bit. Mask bit legend: '0' - do not mask the interrupt. '1' - Mask the related interrupt.
0x14C nab_hint_mask_clr wo
  [31:0] HINT_MASK_CLR_WRCL — Host interrupt mask register clear Writing to this regidster will clear the related interrupt mask bit. Mask bit legend: '0' - do not mask the interrupt. '1' - Mask the related interrupt.
0x150 nab_hint_mask
  [31:0] HINT_MASK — Read mask bitmap. Mask bit legend: '0' - do not mask the interrupt. '1' - Mask the related interrupt.
